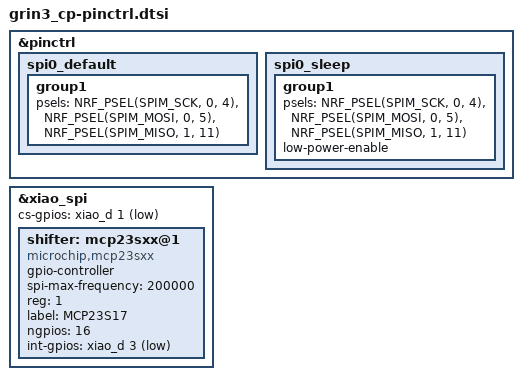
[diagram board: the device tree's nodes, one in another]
&pinctrl {
    spi0_default: spi0_default {
        group1 {
            psels = <NRF_PSEL(SPIM_SCK, 0, 4)>,
                <NRF_PSEL(SPIM_MOSI, 0, 5)>,
                <NRF_PSEL(SPIM_MISO, 1, 11)>;
        };
    };

    spi0_sleep: spi0_sleep {
        group1 {
            psels = <NRF_PSEL(SPIM_SCK, 0, 4)>,
                <NRF_PSEL(SPIM_MOSI, 0, 5)>,
                <NRF_PSEL(SPIM_MISO, 1, 11)>;
            low-power-enable;
        };
    };
};

&xiao_spi {
    status = "okay";
    cs-gpios = <&xiao_d 1 GPIO_ACTIVE_LOW>;

    shifter: mcp23sxx@1 {
        status = "okay";
        compatible = "microchip,mcp23sxx";
        gpio-controller;
        spi-max-frequency = <200000>;
        reg = <1>;
        label = "MCP23S17";
        #gpio-cells = <2>;
        ngpios = <16>;
        int-gpios = <&xiao_d 3 GPIO_ACTIVE_LOW>;
    };
};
